# ATSAMDA1E15B register map
Vendor: Microchip Technology; Series: SAMDA1; File version: 0
CPU: CM0+ r0p0, little endian, no MPU, VTOR, 2 interrupt priority bits, 29 interrupts
Registers are 32-bit, read-write, reset 0x0 unless marked. A register's access mark holds for its fields unless they carry their own. Offsets are from the block's base; [hi:lo] are bit positions; lines under a group give offsets from that group; {n}, {i} and the like mark numbered series; 'fields as' and 'values as' point back to an identical list.

## EVSYS — Event System Interface
Base 0x42000400
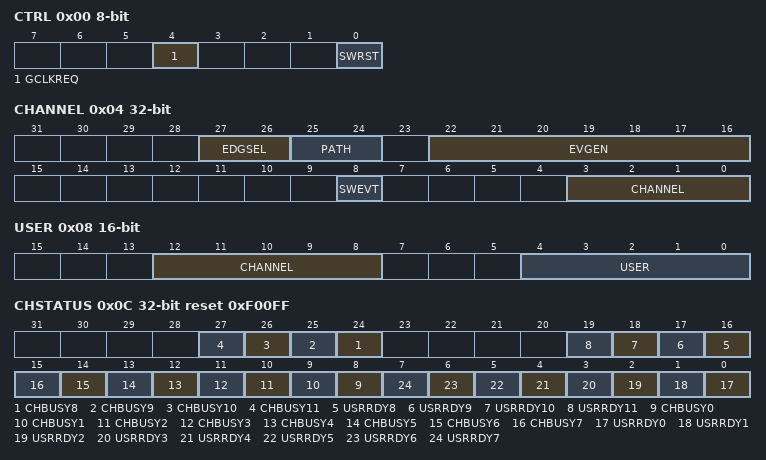
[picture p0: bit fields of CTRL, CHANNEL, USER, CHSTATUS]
0x00 CTRL 8-bit wo — Control
  [4] GCLKREQ — Generic Clock Requests
  [0] SWRST — Software Reset
0x04 CHANNEL
  [27:26] EDGSEL — Edge Detection Selection
    0=NO_EVT_OUTPUT (No event output when using the resynchronized or synchronous path); 1=RISING_EDGE (Event detection only on the rising edge of the signal from the event generator when using the resynchronized or synchronous path); 2=FALLING_EDGE (Event detection only on the falling edge of the signal from the event generator when using the resynchronized or synchronous path); 3=BOTH_EDGES (Event detection on rising and falling edges of the signal from the event generator when using the resynchronized or synchronous path)
  [25:24] PATH — Path Selection
    0=SYNCHRONOUS (Synchronous path); 1=RESYNCHRONIZED (Resynchronized path); 2=ASYNCHRONOUS (Asynchronous path)
  [22:16] EVGEN — Event Generator Selection
  [8] SWEVT — Software Event
  [3:0] CHANNEL — Channel Selection
0x08 USER 16-bit — User Multiplexer
  [12:8] CHANNEL — Channel Event Selection
    0=No Channel Output Selected
  [4:0] USER — User Multiplexer Selection
0x0C CHSTATUS ro reset 0xF00FF — Channel Status
  [n+16] CHBUSY{n} (n=8..11) — Channel {n} Busy
  [n+8] USRRDY{n} (n=8..11) — Channel {n} User Ready
  [n+8] CHBUSY{n} (n=0..7) — Channel {n} Busy
  [n] USRRDY{n} (n=0..7) — Channel {n} User Ready
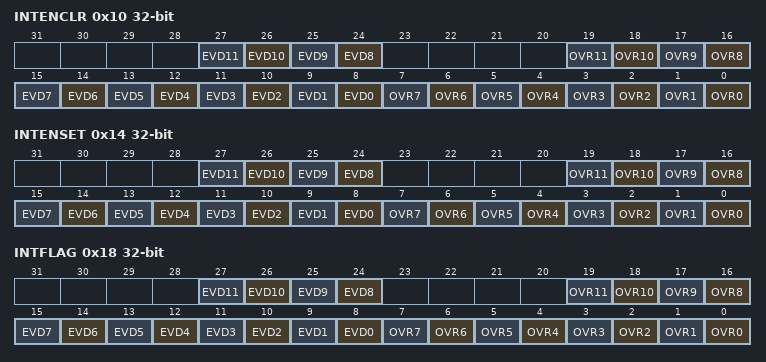
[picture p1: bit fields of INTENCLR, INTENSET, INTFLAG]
0x10 INTENCLR — Interrupt Enable Clear
  [n+16] EVD{n} (n=8..11) — Channel {n} Event Detection Interrupt Enable
  [n+8] OVR{n} (n=8..11) — Channel {n} Overrun Interrupt Enable
  [n+8] EVD{n} (n=0..7) — Channel {n} Event Detection Interrupt Enable
  [n] OVR{n} (n=0..7) — Channel {n} Overrun Interrupt Enable
0x14 INTENSET — Interrupt Enable Set
  fields as INTENCLR
0x18 INTFLAG — Interrupt Flag Status and Clear
  [n+16] EVD{n} (n=8..11) — Channel {n} Event Detection
  [n+8] OVR{n} (n=8..11) — Channel {n} Overrun
  [n+8] EVD{n} (n=0..7) — Channel {n} Event Detection
  [n] OVR{n} (n=0..7) — Channel {n} Overrun

## GCLK — Generic Clock Generator
Base 0x40000C00
0x00 CTRL 8-bit — Control
  [0] SWRST — Software Reset
0x01 STATUS 8-bit ro
  [7] SYNCBUSY — Synchronization Busy Status
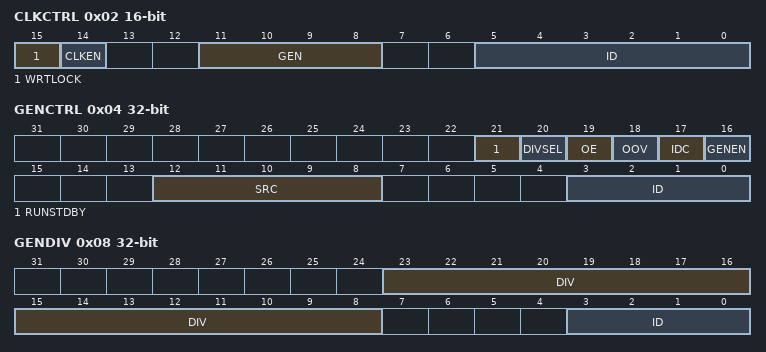
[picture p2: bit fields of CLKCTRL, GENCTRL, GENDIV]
0x02 CLKCTRL 16-bit — Generic Clock Control
  [15] WRTLOCK — Write Lock
  [14] CLKEN — Clock Enable
  [11:8] GEN — Generic Clock Generator
    {v}=GCLK{v} (Generic clock generator {v}) (v=0..8)
  [5:0] ID — Generic Clock Selection ID
    0=DFLL48; 1=FDPLL; 2=FDPLL32K; 3=WDT; 4=RTC; 5=EIC; 6=USB; {v}=EVSYS_{v-7} (v=7..18); 19=SERCOMX_SLOW; {v}=SERCOM{v-20}_CORE (v=20..25); 26=TCC0_TCC1; 27=TCC2_TC3; 28=TC4_TC5; 29=TC6_TC7; 30=ADC; 31=AC_DIG; 32=AC_ANA; 33=DAC; 35=I2S_0; 36=I2S_1
0x04 GENCTRL — Generic Clock Generator Control
  [21] RUNSTDBY — Run in Standby
  [20] DIVSEL — Divide Selection
    0=DIV1 (Divide input directly by divider factor); 1=DIV2 (Divide input by 2^(divider factor+ 1))
  [19] OE — Output Enable
  [18] OOV — Output Off Value
  [17] IDC — Improve Duty Cycle
  [16] GENEN — Generic Clock Generator Enable
  [12:8] SRC — Source Select
    0=XOSC (XOSC oscillator output); 1=GCLKIN (Generator input pad); 2=GCLKGEN1 (Generic clock generator 1 output); 3=OSCULP32K (OSCULP32K oscillator output); 4=OSC32K (OSC32K oscillator output); 5=XOSC32K (XOSC32K oscillator output); 6=OSC8M (OSC8M oscillator output); 7=DFLL48M (DFLL48M output); 8=DPLL96M (DPLL96M output)
  [3:0] ID — Generic Clock Generator Selection
0x08 GENDIV — Generic Clock Generator Division
  [23:8] DIV — Division Factor
  [3:0] ID — Generic Clock Generator Selection

## SBMATRIX — HSB Matrix
Base 0x41007000; register names take the prefix HMATRIXB_
{0x80+8i} PRS[{i}] (i=0..15) group
  0x00 PRAS — Priority A for Slave
  0x04 PRBS — Priority B for Slave
{0x110+4i} SFR[{i}] (i=0..15) — Special Function
  [31:0] SFR — Special Function Register

## Notices in the file
Copyright (c) 2025 Microchip Technology Inc.
SPDX-License-Identifier: Apache-2.0
Licensed under the Apache License, Version 2.0 (the "License");
you may not use this file except in compliance with the License.
You may obtain a copy of the License at
http://www.apache.org/licenses/LICENSE-2.0
Unless required by applicable law or agreed to in writing, software
distributed under the License is distributed on an "AS IS" BASIS,
WITHOUT WARRANTIES OR CONDITIONS OF ANY KIND, either express or implied.
See the License for the specific language governing permissions and
limitations under the License.
